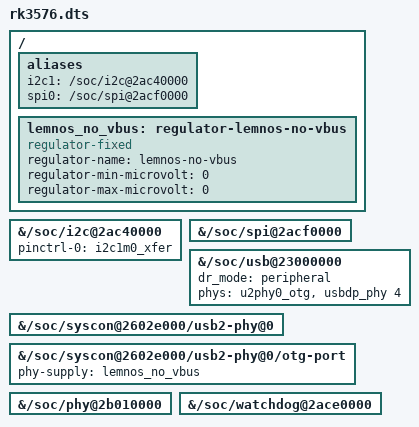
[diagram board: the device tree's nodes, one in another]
// Generated by `lemnos-ctl tree` from board "rk3576". Do not edit: change the
// board file or the SoC map, and generate again.
// Every fragment says why it is here. Node paths are the base tree's.
/dts-v1/;
/plugin/;
/ {
	// i2c: an I2C bus on the RK3576 (rockchip,rk3576-i2c) (alias i2c1, the name "i2c-1") on GPIO10, GPIO11
	fragment@0 {
		target-path = "/soc/i2c@2ac40000";
		__overlay__ {
			status = "okay";
			pinctrl-names = "default";
			pinctrl-0 = <&i2c1m0_xfer>;
		};
	};
	// the runtime name comes out of alias i2c1
	fragment@1 {
		target-path = "/";
		__overlay__ {
			aliases { i2c1 = "/soc/i2c@2ac40000"; };
		};
	};
	// spi: an SPI controller on the RK3576 (alias spi0, the name "spidev0.0")
	fragment@2 {
		target-path = "/soc/spi@2acf0000";
		__overlay__ {
			status = "okay";
		};
	};
	// the runtime name comes out of alias spi0
	fragment@3 {
		target-path = "/";
		__overlay__ {
			aliases { spi0 = "/soc/spi@2acf0000"; };
		};
	};
	// usb-peripheral: the USB DRD (OTG) controller 0 on the RK3576 (rockchip,rk3576-dwc3); device mode
	fragment@4 {
		target-path = "/soc/usb@23000000";
		__overlay__ {
			status = "okay";
			dr_mode = "peripheral";
			phys = <&u2phy0_otg>, <&usbdp_phy 4>;
			phy-names = "usb2-phy", "usb3-phy";
		};
	};
	// needed by usb-drd0 (usb-peripheral): USB 2 PHY 0 (rockchip,rk3576-usb2phy), the USB 2 side of controller 0; disabled in the base tree
	fragment@5 {
		target-path = "/soc/syscon@2602e000/usb2-phy@0";
		__overlay__ {
			status = "okay";
		};
	};
	// the stand-in for a device port's VBUS supply: a fixed regulator with no enable pin, no GPIO and no voltage; it supplies nothing
	fragment@6 {
		target-path = "/";
		__overlay__ {
			lemnos_no_vbus: regulator-lemnos-no-vbus { compatible = "regulator-fixed"; regulator-name = "lemnos-no-vbus"; regulator-min-microvolt = <0>; regulator-max-microvolt = <0>; };
		};
	};
	// needed by usb-drd0 (usb-peripheral): the OTG port of USB 2 PHY 0, the one controller 0 is wired to (its phys); its phy-supply is replaced by the stand-in, so this PHY drives no VBUS
	fragment@7 {
		target-path = "/soc/syscon@2602e000/usb2-phy@0/otg-port";
		__overlay__ {
			status = "okay";
			phy-supply = <&lemnos_no_vbus>;
		};
	};
	// needed by usb-drd0 (usb-peripheral): the USBDP combo PHY (rockchip,rk3576-usbdp-phy), the SuperSpeed side of controller 0; the board names usb3 (its phys, PHY_TYPE_USB3)
	fragment@8 {
		target-path = "/soc/phy@2b010000";
		__overlay__ {
			status = "okay";
		};
	};
	// watchdog: the hardware watchdog on the RK3576 (rockchip,rk3576-wdt, snps,dw-wdt)
	fragment@9 {
		target-path = "/soc/watchdog@2ace0000";
		__overlay__ {
			status = "okay";
		};
	};
};
